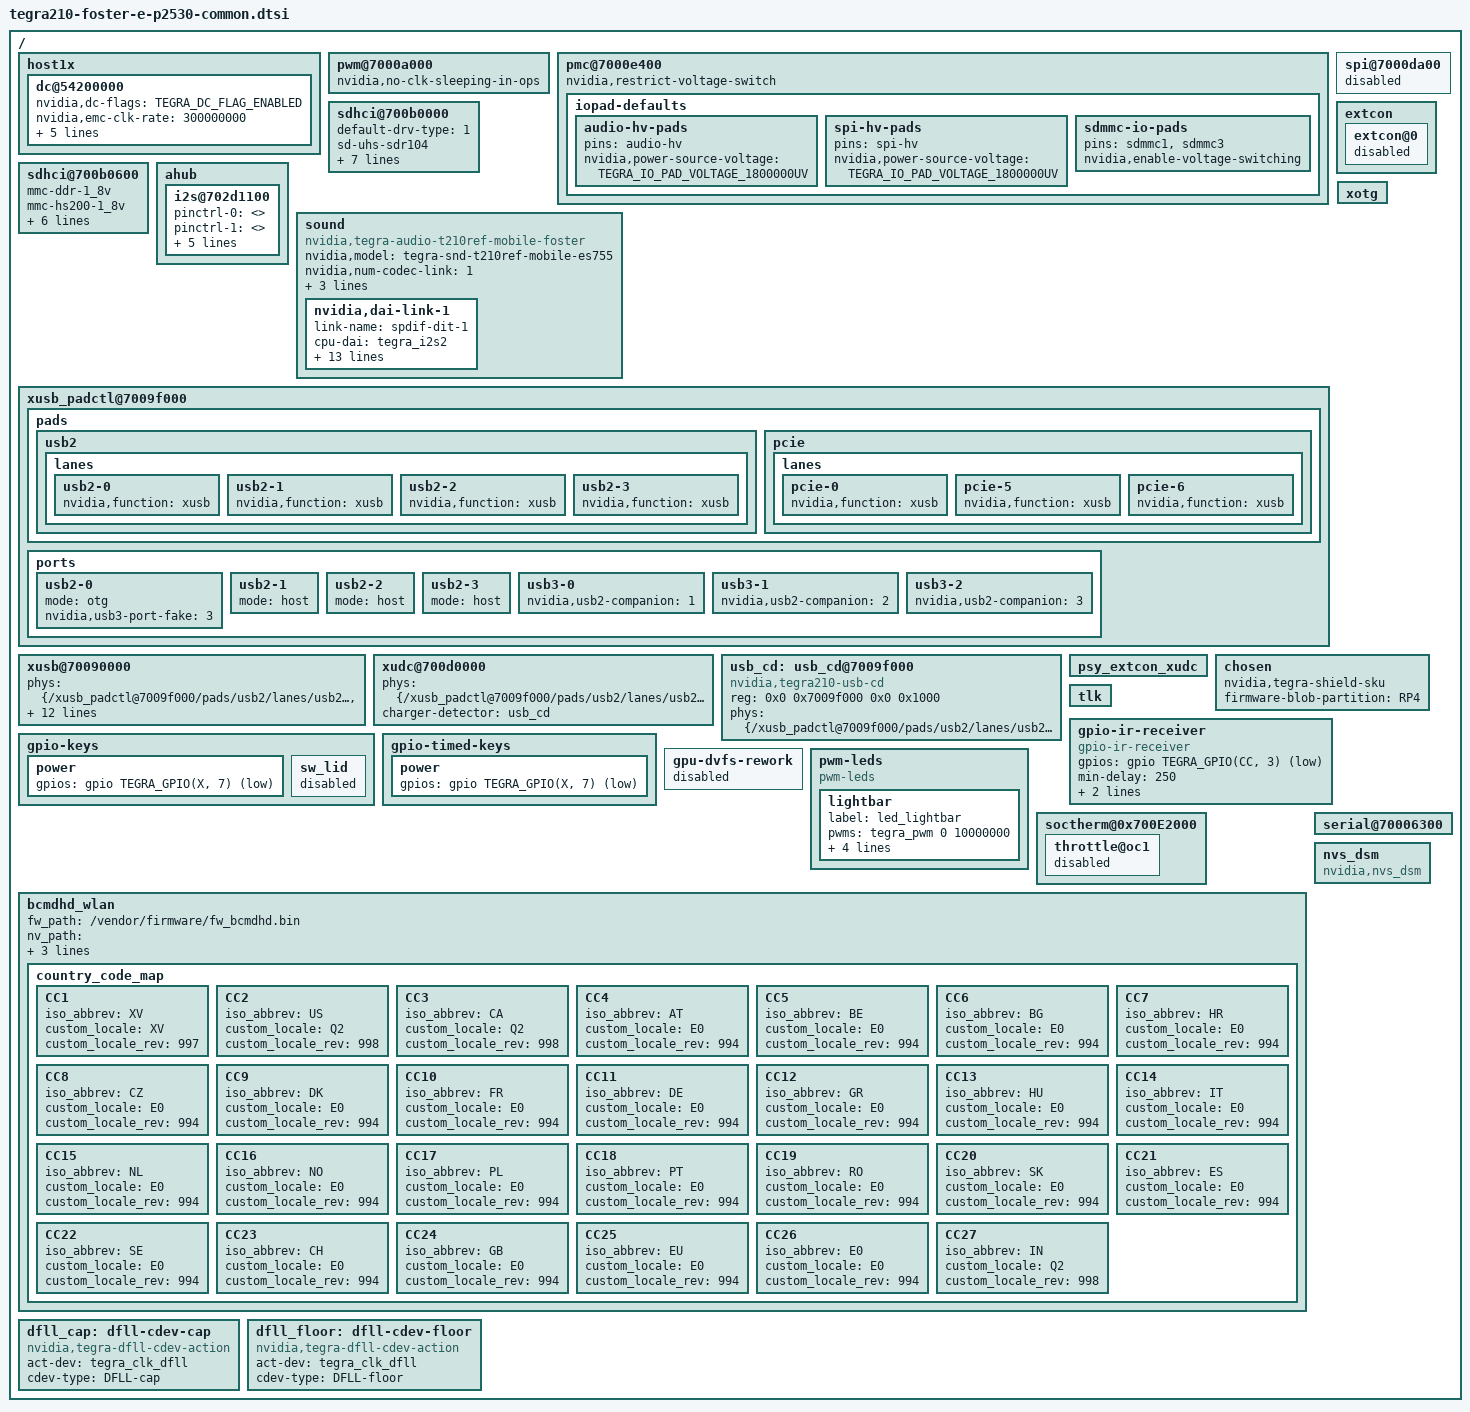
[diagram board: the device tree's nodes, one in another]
/*
 * arch/arm64/boot/dts/tegra210-foster-e-p2530-common.dtsi
 *
 * Copyright (c) 2014-2018, NVIDIA CORPORATION.  All rights reserved.
 *
 * This program is free software; you can redistribute it and/or modify
 * it under the terms of the GNU General Public License as published by
 * the Free Software Foundation; version 2 of the License.
 *
 * This program is distributed in the hope that it will be useful, but WITHOUT
 * ANY WARRANTY; without even the implied warranty of MERCHANTABILITY or
 * FITNESS FOR A PARTICULAR PURPOSE.  See the GNU General Public License for
 * more details.
 *
 * You should have received a copy of the GNU General Public License along
 * with this program; if not, write to the Free Software Foundation, Inc.,
 * 51 Franklin Street, Fifth Floor, Boston, MA  02110-1301, USA.
 *
 */

/dts-v1/;

/memreserve/ 0x80000000 0x00020000;

#include <t210-common-platforms/tegra210-common.dtsi>
#include "foster-platforms/tegra210-foster-e-prods.dtsi"
#include <tegra210-soc/tegra210-sdhci.dtsi>
#include <t210-common-platforms/tegra210-p2530-common.dtsi>
#include "foster-platforms/tegra210-foster-e-power-tree-p2530-0932-e00.dtsi"
#include "foster-platforms/tegra210-foster-e-gpio-p2530-0930-e00.dtsi"
#include "foster-platforms/tegra210-foster-e-pinmux-p2530-0930-e00.dtsi"
#include "foster-platforms/tegra210-loki-e-comms.dtsi"
#include "foster-platforms/tegra210-foster-e-pwm-fan.dtsi"
#include "foster-platforms/tegra210-foster-e-camera.dtsi"
#include <t210-common-platforms/tegra210-ers-hdmi-e2190-1100-a00.dtsi>
#include "foster-platforms/tegra210-foster-e-thermal-fan-est.dtsi"
#include "foster-platforms/tegra210-loki-e-keys-p2530-0032-e00.dtsi"
#include <dt-bindings/iio/meter/ina3221x.h>
#include <tegra210-soc/tegra210-audio.dtsi>
#include <tegra210-soc/tegra210-soc-sata.dtsi>
#include "foster-platforms/tegra210-foster-cpufreq.dtsi"

/ {
	host1x {
		/* tegradc.0 */
		dc@54200000 {
			status = "okay";
			nvidia,dc-flags = <TEGRA_DC_FLAG_ENABLED>;
			nvidia,emc-clk-rate = <300000000>;
			nvidia,cmu-enable = <1>;
			nvidia,fb-bpp = <32>; /* bits per pixel */
			nvidia,fb-flags = <TEGRA_FB_FLIP_ON_PROBE>;
			nvidia,dc-or-node = "/host1x/sor1";
			nvidia,50hz-ss-war;
		};
	};

	pwm@7000a000 {
		nvidia,no-clk-sleeping-in-ops;
	};

	pmc@7000e400 {
		nvidia,restrict-voltage-switch;
		iopad-defaults {
			audio-hv-pads {
				pins = "audio-hv";
				nvidia,power-source-voltage = <TEGRA_IO_PAD_VOLTAGE_1800000UV>;
			};

			spi-hv-pads {
				pins = "spi-hv";
				nvidia,power-source-voltage = <TEGRA_IO_PAD_VOLTAGE_1800000UV>;
			};

			sdmmc-io-pads {
				pins = "sdmmc1", "sdmmc3";
				nvidia,enable-voltage-switching;
			};
		};
	};

	spi@7000da00 {
		status = "disabled";
	};

	sdhci@700b0000 {
		default-drv-type = <1>;
		sd-uhs-sdr104;
		sd-uhs-sdr50;
		sd-uhs-sdr25;
		sd-uhs-sdr12;
		mmc-ddr-1_8v;
		mmc-hs200-1_8v;
		no-sdio;
		no-mmc;
	};

	sdhci@700b0600 {
		mmc-ddr-1_8v;
		mmc-hs200-1_8v;
		mmc-hs400-1_8v;
		no-sdio;
		no-sd;
		nvidia,enable-hwcq;
		non-removable;
		mmc-hs400-enhanced-strobe;
	};

	ahub {
		i2s@702d1100 {
			pinctrl-names = "dap_active", "dap_inactive";
			pinctrl-0 = <>;
			pinctrl-1 = <>;
			regulator-supplies = "vdd-1v8-spi-hv", "vdd-1v8-spi-hv-bias";
			vdd-1v8-spi-hv-supply = <&max77620_sd3>;
			vdd-1v8-spi-hv-bias-supply = <&max77620_sd3>;
			fsync-width = <0>;
		};
	};

	sound {
		compatible = "nvidia,tegra-audio-t210ref-mobile-foster";
		nvidia,model = "tegra-snd-t210ref-mobile-es755";
		nvidia,num-codec-link = <1>;

		nvidia,audio-routing =
			"y Headphone", 	"y OUT",
			"y IN",		"y Mic";

		nvidia,xbar = <&tegra_axbar>;

		nvidia,dai-link-1 {
			link-name = "spdif-dit-1";
			cpu-dai = <&tegra_i2s2>;
			codec-dai = <&spdif_dit1>;
			cpu-dai-name = "I2S2";
			codec-dai-name = "dit-hifi";
			format = "dsp_a";
			bitclock-slave;
			frame-slave;
			bitclock-inversion;
			frame-noninversion;
			bit-format = "s16_le";
			bclk_ratio = <4>;
			srate = <8000>;
			num-channel = <1>;
			name-prefix = "y";
		};
	};

	extcon {
		extcon@0 {
			status = "disabled";
		};
	};

	xusb_padctl@7009f000 {
		status = "okay";

		pads {
			usb2 {
				status = "okay";

				lanes {
					usb2-0 {
						status = "okay";
						nvidia,function = "xusb";
					};
					usb2-1 {
						status = "okay";
						nvidia,function = "xusb";
					};
					usb2-2 {
						status = "okay";
						nvidia,function = "xusb";
					};
					usb2-3 {
						status = "okay";
						nvidia,function = "xusb";
					};
				};
			};

			pcie {
				status = "okay";

				lanes {
					pcie-0 {
						status = "okay";
						nvidia,function = "xusb";
					};
					pcie-5 {
						status = "okay";
						nvidia,function = "xusb";
					};
					pcie-6 {
						status = "okay";
						nvidia,function = "xusb";
					};
				};
			};
		};

		ports {
			usb2-0 {
				status = "okay";
				mode = "otg";
				nvidia,usb3-port-fake = <3>;
			};
			usb2-1 {
				status = "okay";
				mode = "host";
			};
			usb2-2 {
				status = "okay";
				mode = "host";
			};
			usb2-3 {
				status = "okay";
				mode = "host";
			};
			usb3-0 {
				status = "okay";
				nvidia,usb2-companion = <1>;
			};
			usb3-1 {
				status = "okay";
				nvidia,usb2-companion = <2>;
			};
			usb3-2 {
				status = "okay";
				nvidia,usb2-companion = <3>;
			};
		};
	};

	xusb@70090000 {
		phys = <&{/xusb_padctl@7009f000/pads/usb2/lanes/usb2-0}>,
				<&{/xusb_padctl@7009f000/pads/usb2/lanes/usb2-1}>,
				<&{/xusb_padctl@7009f000/pads/usb2/lanes/usb2-2}>,
				<&{/xusb_padctl@7009f000/pads/usb2/lanes/usb2-3}>,
				<&{/xusb_padctl@7009f000/pads/pcie/lanes/pcie-6}>,
				<&{/xusb_padctl@7009f000/pads/pcie/lanes/pcie-5}>,
				<&{/xusb_padctl@7009f000/pads/pcie/lanes/pcie-0}>;
		phy-names = "usb2-0", "usb2-1", "usb2-2", "usb2-3", "usb3-0", "usb3-1", "usb3-2";
		#extcon-cells = <1>;
		nvidia,pmc-wakeup =
			<&tegra_pmc
				PMC_WAKE_TYPE_EVENT 39 PMC_TRIGGER_TYPE_HIGH>,
			<&tegra_pmc
				PMC_WAKE_TYPE_EVENT 40 PMC_TRIGGER_TYPE_HIGH>,
			<&tegra_pmc
				PMC_WAKE_TYPE_EVENT 41 PMC_TRIGGER_TYPE_HIGH>,
			<&tegra_pmc
				PMC_WAKE_TYPE_EVENT 42 PMC_TRIGGER_TYPE_HIGH>,
			<&tegra_pmc
				PMC_WAKE_TYPE_EVENT 44 PMC_TRIGGER_TYPE_HIGH>;
		status = "okay";
	};

	xudc@700d0000 {
		phys =  <&{/xusb_padctl@7009f000/pads/usb2/lanes/usb2-0}>;
		phy-names = "usb2";
		charger-detector = <&usb_cd>;
		#extcon-cells = <1>;
		status = "okay";
	};

	usb_cd: usb_cd@7009f000 {
		compatible = "nvidia,tegra210-usb-cd";
		reg = <0x0 0x7009f000 0x0 0x1000>;
		phys = <&{/xusb_padctl@7009f000/pads/usb2/lanes/usb2-0}>;
		phy-names = "otg-phy";
		status = "okay";
	};

	psy_extcon_xudc {
		/delete-property/ dt-override-status-odm-data;
	};

	xotg {
		#extcon-cells = <1>;
	};

	chosen {
		nvidia,tegra-shield-sku;
		firmware-blob-partition = "RP4";
        };

	tlk {
		status = "okay";
	};

	gpio-ir-receiver {
		compatible = "gpio-ir-receiver";
		status = "okay";
		gpios = <&gpio TEGRA_GPIO(CC, 3) GPIO_ACTIVE_LOW>;
		min-delay = <250>;
		linux,rc-map-name = "rc-nvidia-nec";
		allowed-protos = <0x0 0x400>;
	};

	gpio-keys {
		power {
			gpios = <&gpio TEGRA_GPIO(X, 7) GPIO_ACTIVE_LOW>;
		};

		sw_lid {
			status="disabled";
		};
	};

	gpio-timed-keys {
		power {
			gpios = <&gpio TEGRA_GPIO(X, 7) GPIO_ACTIVE_LOW>;
		};
	};

	gpu-dvfs-rework {
		status = "disabled";
	};
	pwm-leds {
		compatible = "pwm-leds";
		lightbar {
			label = "led_lightbar";
			pwms = <&tegra_pwm 0 10000000>;
			gpios = <&gpio TEGRA_GPIO(V, 0) GPIO_ACTIVE_LOW>;
			max-brightness = <255>;
			default-brightness = <255>;
			linux,default-trigger = "default-on";
		};
	};

	soctherm@0x700E2000 {
		throttle@oc1 {
			status = "disabled";
		};
	};

	bcmdhd_wlan {
		fw_path = "/vendor/firmware/fw_bcmdhd.bin";
		nv_path = "/vendor/firmware/nvram_foster_e_4354.txt";
		tuned_nv_path = "/vendor/firmware/nvram_foster_e_antenna_tuned_4354.txt";
		country_code_map {
			CC1 {
				iso_abbrev = "XV";
				custom_locale = "XV";
				custom_locale_rev = <997>;
			};
			CC2 {
				iso_abbrev = "US";
				custom_locale = "Q2";
				custom_locale_rev = <998>;
			};
			CC3 {
				iso_abbrev = "CA";
				custom_locale = "Q2";
				custom_locale_rev = <998>;
			};
			CC4 {
				iso_abbrev = "AT";
				custom_locale = "E0";
				custom_locale_rev = <994>;
			};
			CC5 {
				iso_abbrev = "BE";
				custom_locale = "E0";
				custom_locale_rev = <994>;
			};
			CC6 {
				iso_abbrev = "BG";
				custom_locale = "E0";
				custom_locale_rev = <994>;
			};
			CC7 {
				iso_abbrev = "HR";
				custom_locale = "E0";
				custom_locale_rev = <994>;
			};
			CC8 {
				iso_abbrev = "CZ";
				custom_locale = "E0";
				custom_locale_rev = <994>;
			};
			CC9 {
				iso_abbrev = "DK";
				custom_locale = "E0";
				custom_locale_rev = <994>;
			};
			CC10 {
				iso_abbrev = "FR";
				custom_locale = "E0";
				custom_locale_rev = <994>;
			};
			CC11 {
				iso_abbrev = "DE";
				custom_locale = "E0";
				custom_locale_rev = <994>;
			};
			CC12 {
				iso_abbrev = "GR";
				custom_locale = "E0";
				custom_locale_rev = <994>;
			};
			CC13 {
				iso_abbrev = "HU";
				custom_locale = "E0";
				custom_locale_rev = <994>;
			};
			CC14 {
				iso_abbrev = "IT";
				custom_locale = "E0";
				custom_locale_rev = <994>;
			};
			CC15 {
				iso_abbrev = "NL";
				custom_locale = "E0";
				custom_locale_rev = <994>;
			};
			CC16 {
				iso_abbrev = "NO";
				custom_locale = "E0";
				custom_locale_rev = <994>;
			};
			CC17 {
				iso_abbrev = "PL";
				custom_locale = "E0";
				custom_locale_rev = <994>;
			};
			CC18 {
				iso_abbrev = "PT";
				custom_locale = "E0";
				custom_locale_rev = <994>;
			};
			CC19 {
				iso_abbrev = "RO";
				custom_locale = "E0";
				custom_locale_rev = <994>;
			};
			CC20 {
				iso_abbrev = "SK";
				custom_locale = "E0";
				custom_locale_rev = <994>;
			};
			CC21 {
				iso_abbrev = "ES";
				custom_locale = "E0";
				custom_locale_rev = <994>;
			};
			CC22 {
				iso_abbrev = "SE";
				custom_locale = "E0";
				custom_locale_rev = <994>;
			};
			CC23 {
				iso_abbrev = "CH";
				custom_locale = "E0";
				custom_locale_rev = <994>;
			};
			CC24 {
				iso_abbrev = "GB";
				custom_locale = "E0";
				custom_locale_rev = <994>;
			};
			CC25 {
				iso_abbrev = "EU";
				custom_locale = "E0";
				custom_locale_rev = <994>;
			};
			CC26 {
				iso_abbrev = "E0";
				custom_locale = "E0";
				custom_locale_rev = <994>;
			};
			CC27 {
				iso_abbrev = "IN";
				custom_locale = "Q2";
				custom_locale_rev = <998>;
			};
		};
	};

	serial@70006300 {
		dma-names = "tx";
	};

	nvs_dsm {
		compatible = "nvidia,nvs_dsm";
		status = "okay";
	};

	dfll_cap: dfll-cdev-cap {
		compatible = "nvidia,tegra-dfll-cdev-action";
		act-dev = <&tegra_clk_dfll>;
		cdev-type = "DFLL-cap";
		#cooling-cells = <2>; /* min followed by max */
	};

	dfll_floor: dfll-cdev-floor {
		compatible = "nvidia,tegra-dfll-cdev-action";
		act-dev = <&tegra_clk_dfll>;
		cdev-type = "DFLL-floor";
		#cooling-cells = <2>; /* min followed by max */
	};
};
